VERSION "1.0 test"

NS_ :

BS_:

BU_: ECU1 ECU2 Gateway

VAL_TABLE_ OnOff 1 "On" 0 "Off" ;

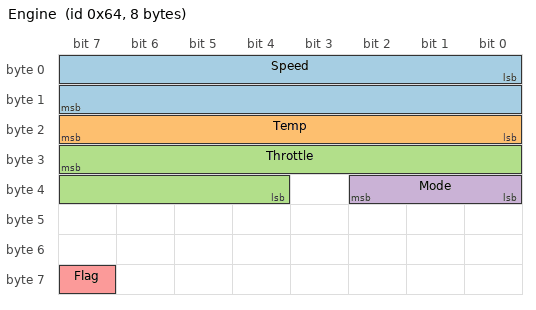
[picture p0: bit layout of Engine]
BO_ 100 Engine: 8 ECU1
 SG_ Speed : 0|16@1+ (0.125,0) [0|8191.875] "rpm" ECU2,Gateway
 SG_ Temp : 16|8@1- (1,-40) [-40|87] "degC" ECU2
 SG_ Throttle : 31|12@0+ (0.1,0) [0|409.5] "%" Vector__XXX
 SG_ Mode : 32|3@1+ (1,0) [0|7] "" ECU2
 SG_ Flag : 63|1@0+ (1,0) [0|1] "" ECU2

BO_ 2566844926 Wide: 8 ECU2
 SG_ U64 : 0|64@1+ (1,0) [0|0] "" ECU1
BO_ 200 SignedBE: 8 ECU2
 SG_ S64 : 7|64@0- (1,0) [0|0] "" ECU1

BO_ 300 Floats: 12 Gateway
 SG_ F32 : 0|32@1- (1,0) [0|0] "" ECU1
 SG_ F64 : 39|64@0- (2,1) [0|0] "" ECU1

BO_ 400 Muxed: 8 ECU1
 SG_ Sel M : 0|8@1+ (1,0) [0|255] "" ECU2
 SG_ A m0 : 8|16@1+ (1,0) [0|65535] "" ECU2
 SG_ B m1 : 8|8@1- (1,0) [-128|127] "" ECU2
 SG_ C : 56|8@1+ (1,0) [0|255] "" ECU2

BO_ 500 ExtMux: 8 ECU1
 SG_ Outer M : 0|4@1+ (1,0) [0|15] "" ECU2
 SG_ Inner m1M : 4|4@1+ (1,0) [0|15] "" ECU2
 SG_ Deep m2 : 8|8@1+ (1,0) [0|255] "" ECU2
 SG_ Other m3 : 8|16@1+ (1,0) [0|65535] "" ECU2

BO_ 2147484160 FdMsg: 64 ECU1
 SG_ First : 0|8@1+ (1,0) [0|255] "" ECU2
 SG_ Last : 511|8@0+ (1,0) [0|255] "" ECU2

BO_ 3221225472 VECTOR__INDEPENDENT_SIG_MSG: 0 Vector__XXX
 SG_ Orphan : 0|8@1+ (1,0) [0|0] "" Vector__XXX

BO_TX_BU_ 100 : ECU1,Gateway;

CM_ "Network comment";
CM_ BU_ ECU1 "Engine control unit";
CM_ BO_ 100 "Engine data";
CM_ SG_ 100 Speed "Engine speed
on two lines with a \"quote\"";
BA_DEF_ BO_ "GenMsgCycleTime" INT 0 65535;
BA_DEF_ SG_ "GenSigStartValue" INT -2147483648 2147483647;
BA_DEF_ BO_ "VFrameFormat" ENUM "StandardCAN","ExtendedCAN","reserved","reserved","reserved","reserved","reserved","reserved","reserved","reserved","reserved","reserved","reserved","reserved","StandardCAN_FD","ExtendedCAN_FD";
BA_DEF_ BO_ "CANFD_BRS" ENUM "0","1";
BA_DEF_  "BusType" STRING ;
BA_DEF_ BU_ "NodeLayer" HEX 0 255;
BA_DEF_ SG_ "Precision" FLOAT 0 1;
BA_DEF_DEF_ "GenMsgCycleTime" 0;
BA_DEF_DEF_ "GenSigStartValue" 0;
BA_DEF_DEF_ "VFrameFormat" "StandardCAN";
BA_DEF_DEF_ "CANFD_BRS" "1";
BA_DEF_DEF_ "BusType" "CAN FD";
BA_ "NodeLayer" BU_ ECU1 16;
BA_ "GenMsgCycleTime" BO_ 100 10;
BA_ "GenSigStartValue" SG_ 100 Temp 40;
BA_ "Precision" SG_ 100 Speed 0.5;
BA_ "VFrameFormat" BO_ 2147484160 15;
VAL_ 100 Mode 0 "Off" 1 "Idle" 2 "Run" 7 "Fault" ;
VAL_ 400 Sel 0 "PageA" 1 "PageB" ;
SIG_VALTYPE_ 300 F32 : 1;
SIG_VALTYPE_ 300 F64 : 2;
SG_MUL_VAL_ 500 Inner Outer 1-1;
SG_MUL_VAL_ 500 Deep Inner 2-2, 5-6;
SG_MUL_VAL_ 500 Other Inner 3-4;
SIG_GROUP_ 100 Group1 1 : Speed Temp;
EV_ EnvVar1: 0 [0|1] "" 0 1 DUMMY_NODE_VECTOR0 Vector__XXX;
